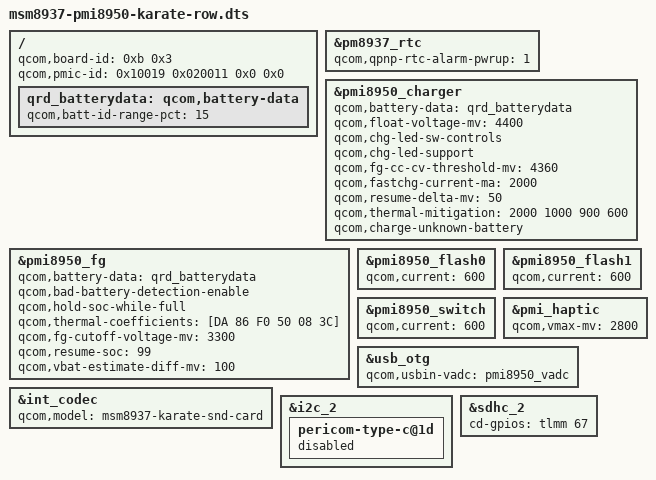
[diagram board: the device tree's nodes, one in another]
/* Copyright (c) 2015, Lenovo mobile Inc. All rights reserved.
 *
 * This program is free software; you can redistribute it and/or modify
 * it under the terms of the GNU General Public License version 2 and
 * only version 2 as published by the Free Software Foundation.
 *
 * This program is distributed in the hope that it will be useful,
 * but WITHOUT ANY WARRANTY; without even the implied warranty of
 * MERCHANTABILITY or FITNESS FOR A PARTICULAR PURPOSE.  See the
 * GNU General Public License for more details.
 */

/dts-v1/;

#include "karate/msm8937-pmi8950-karate-row.dtsi"

/ {
	qcom,board-id= <0xb 0x3>;
	qcom,pmic-id = <0x10019 0x020011 0x0 0x0>;
};

/ {
	qrd_batterydata: qcom,battery-data {
		qcom,batt-id-range-pct = <15>;
		#include "karate/batterydata-bl267-karate-3080mah.dtsi"
		#include "karate/batterydata-bl267-karate-2-3080mah.dtsi"
		#include "karate/batterydata-bl272scud-karate_power-4000mah.dtsi"
		#include "karate/batterydata-bl272vk-karate-4000mah.dtsi"
	};
};

&pm8937_rtc {
        qcom,qpnp-rtc-alarm-pwrup = <1>;
};

&pmi8950_charger {
	qcom,battery-data = <&qrd_batterydata>;
	qcom,float-voltage-mv = <4400>;
	qcom,chg-led-sw-controls;
	qcom,chg-led-support;
	qcom,fg-cc-cv-threshold-mv = <4360>;
	qcom,fastchg-current-ma = <2000>;
	qcom,resume-delta-mv = <50>;
	qcom,thermal-mitigation = <2000 1000 900 600>;
	/delete-property/ qcom,parallel-usb-min-current-ma;
	/delete-property/ qcom,parallel-usb-9v-min-current-ma;
	/delete-property/ qcom,parallel-allowed-lowering-ma;
	qcom,charge-unknown-battery;
	status = "okay";
};

&pmi8950_fg {
	qcom,battery-data = <&qrd_batterydata>;
	qcom,bad-battery-detection-enable;
	qcom,hold-soc-while-full;
	qcom,thermal-coefficients = [DA 86 F0 50 08 3C];
	qcom,fg-cutoff-voltage-mv = <3300>;
	qcom,resume-soc = <99>;
	qcom,vbat-estimate-diff-mv = <100>;
};

&pmi8950_flash0 {
	qcom,current = <600>;
};

&pmi8950_flash1 {
	qcom,current = <600>;
};

&pmi8950_switch {
	qcom,current = <600>;
};

&pmi_haptic {
	qcom,vmax-mv = <2800>;
};

&usb_otg {
        qcom,usbin-vadc = <&pmi8950_vadc>;
};

&int_codec {
	qcom,model = "msm8937-karate-snd-card";
};

&i2c_2 {
	pericom-type-c@1d {
		status="disabled";
	};
};

&sdhc_2 {
	cd-gpios = <&tlmm 67 0>; /* Active High */
};
